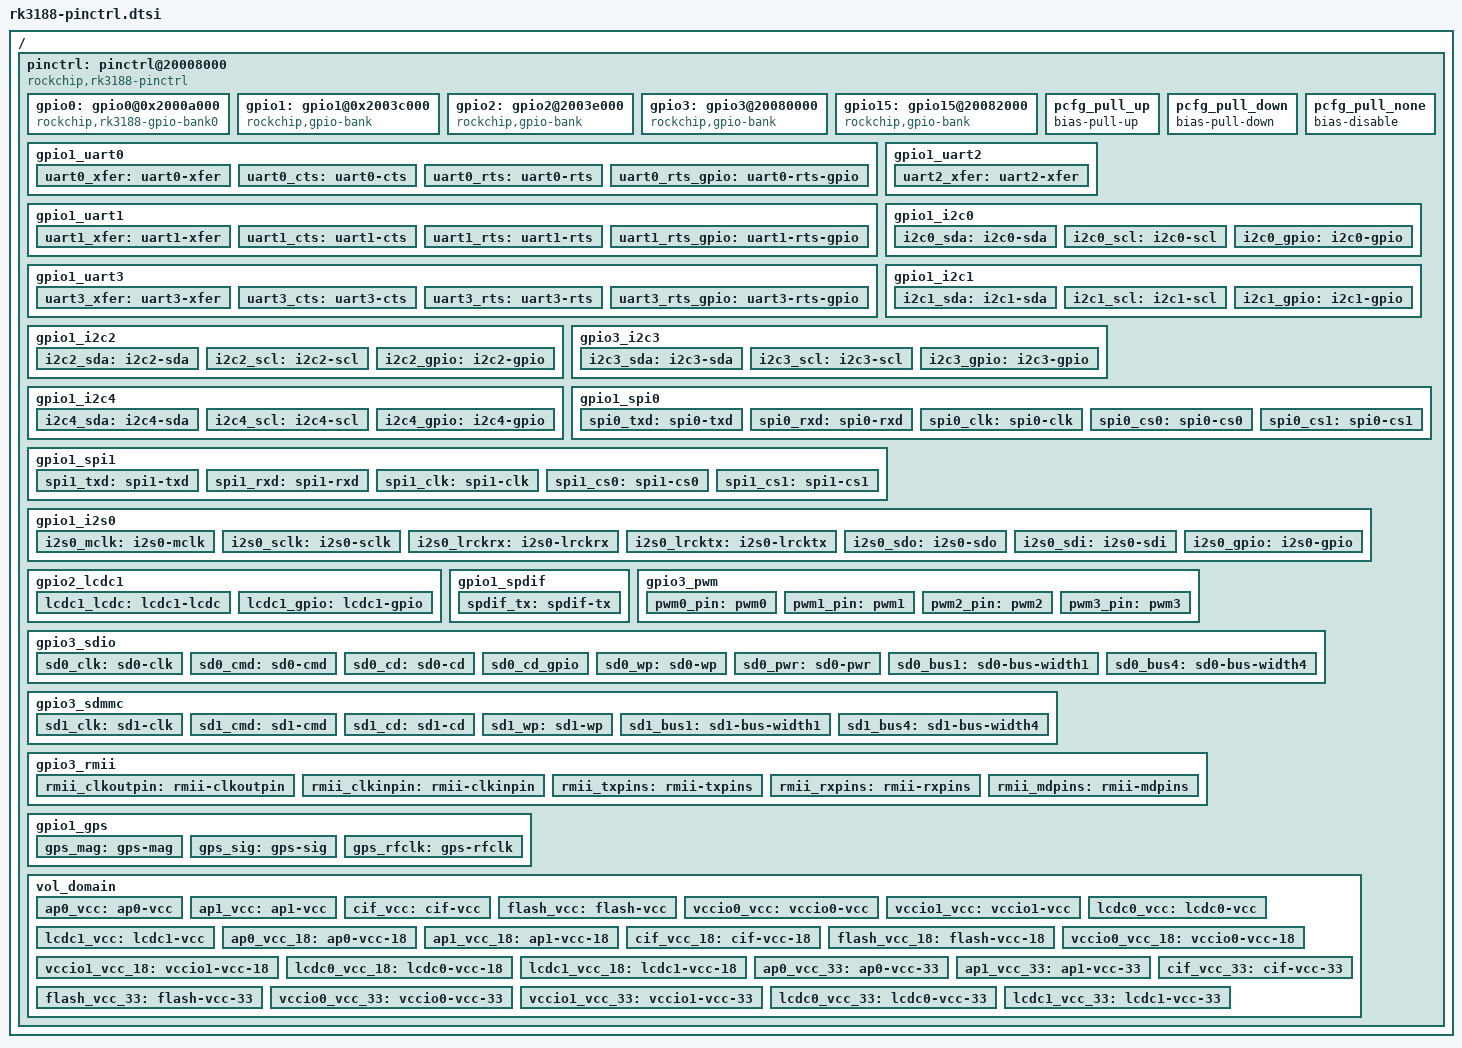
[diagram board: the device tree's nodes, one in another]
#include <dt-bindings/interrupt-controller/arm-gic.h>
#include <dt-bindings/gpio/gpio.h>
#include <dt-bindings/pinctrl/rockchip.h>
#include <dt-bindings/pinctrl/rockchip-rk3188.h>

/ { 
	pinctrl: pinctrl@20008000 {
		compatible = "rockchip,rk3188-pinctrl";
		reg = <0x20008000 0x60>,
		      <0x20008060 0x40>,
		      <0x20008164 0x40>,
		      <0x200080f4 0x10>;
		reg-names = "base", "mux", "pull", "drv";
		#address-cells = <1>;
		#size-cells = <1>;
		ranges;

		gpio0: gpio0@0x2000a000 {
			compatible = "rockchip,rk3188-gpio-bank0";
			reg = <0x2000a000 0x100>,
			      <0x20004064 0x8>;
			reg-names = "base", "pull_bank0";
			interrupts = <GIC_SPI 54 IRQ_TYPE_LEVEL_HIGH>;
			clocks = <&clk_gates8 9>;

			gpio-controller;
			#gpio-cells = <2>;

			interrupt-controller;
			#interrupt-cells = <2>;
		};

		gpio1: gpio1@0x2003c000 {
			compatible = "rockchip,gpio-bank";
			reg = <0x2003c000 0x100>;
			interrupts = <GIC_SPI 55 IRQ_TYPE_LEVEL_HIGH>;
			clocks = <&clk_gates8 10>;

			gpio-controller;
			#gpio-cells = <2>;

			interrupt-controller;
			#interrupt-cells = <2>;
		};

		gpio2: gpio2@2003e000 {
			compatible = "rockchip,gpio-bank";
			reg = <0x2003e000 0x100>;
			interrupts = <GIC_SPI 56 IRQ_TYPE_LEVEL_HIGH>;
			clocks = <&clk_gates8 11>;

			gpio-controller;
			#gpio-cells = <2>;

			interrupt-controller;
			#interrupt-cells = <2>;
		};

		gpio3: gpio3@20080000 {
			compatible = "rockchip,gpio-bank";
			reg = <0x20080000 0x100>;
			interrupts = <GIC_SPI 57 IRQ_TYPE_LEVEL_HIGH>;
			clocks = <&clk_gates8 12>;

			gpio-controller;
			#gpio-cells = <2>;

			interrupt-controller;
			#interrupt-cells = <2>;
		};

		gpio15: gpio15@20082000 {
			compatible = "rockchip,gpio-bank";
			reg = <0x20082000 0x100>;
			interrupts = <GIC_SPI 127 IRQ_TYPE_LEVEL_HIGH>;//127 = 160-32-1
			clocks = <&clk_gates8 12>;

			gpio-controller;
			#gpio-cells = <2>;

			interrupt-controller;
			#interrupt-cells = <2>;
		};

		pcfg_pull_up: pcfg_pull_up {
			bias-pull-up;
		};

		pcfg_pull_down: pcfg_pull_down {
			bias-pull-down;
		};

		pcfg_pull_none: pcfg_pull_none {
			bias-disable;
		};

		gpio1_uart0 {
			uart0_xfer: uart0-xfer {
				rockchip,pins = <UART0_SIN>,
						<UART0_SOUT>;
				rockchip,pull = <VALUE_PULL_DISABLE>;
				rockchip,voltage = <VALUE_VOL_DEFAULT>;
				rockchip,drive = <VALUE_DRV_DEFAULT>;
				//rockchip,tristate = <VALUE_TRI_DEFAULT>;
			};

			uart0_cts: uart0-cts {
				rockchip,pins = <UART0_CTSN>;
				rockchip,pull = <VALUE_PULL_DISABLE>;
				//rockchip,voltage = <VALUE_VOL_DEFAULT>;
				rockchip,drive = <VALUE_DRV_DEFAULT>;
				//rockchip,tristate = <VALUE_TRI_DEFAULT>;
			};

			uart0_rts: uart0-rts {
				rockchip,pins = <UART0_RTSN>;
				rockchip,pull = <VALUE_PULL_DISABLE>;
				//rockchip,voltage = <VALUE_VOL_DEFAULT>;
				rockchip,drive = <VALUE_DRV_DEFAULT>;
				//rockchip,tristate = <VALUE_TRI_DEFAULT>;
			};

			uart0_rts_gpio: uart0-rts-gpio {
				rockchip,pins = <FUNC_TO_GPIO(UART0_RTSN)>;
				rockchip,drive = <VALUE_DRV_DEFAULT>;
			};
		};

		gpio1_uart1 {
			uart1_xfer: uart1-xfer {
				rockchip,pins = <UART1_SIN>,
						<UART1_SOUT>;
				rockchip,pull = <VALUE_PULL_DISABLE>;
				//rockchip,voltage = <VALUE_VOL_DEFAULT>;
				rockchip,drive = <VALUE_DRV_DEFAULT>;
				//rockchip,tristate = <VALUE_TRI_DEFAULT>;
			};

			uart1_cts: uart1-cts {
				rockchip,pins = <UART1_CTSN>;
				rockchip,pull = <VALUE_PULL_DISABLE>;
				//rockchip,voltage = <VALUE_VOL_DEFAULT>;
				rockchip,drive = <VALUE_DRV_DEFAULT>;
				//rockchip,tristate = <VALUE_TRI_DEFAULT>;
			};

			uart1_rts: uart1-rts {
				rockchip,pins = <UART1_RTSN>;
				rockchip,pull = <VALUE_PULL_DISABLE>;
				//rockchip,voltage = <VALUE_VOL_DEFAULT>;
				rockchip,drive = <VALUE_DRV_DEFAULT>;
				//rockchip,tristate = <VALUE_TRI_DEFAULT>;
			};

			uart1_rts_gpio: uart1-rts-gpio {
				rockchip,pins = <FUNC_TO_GPIO(UART1_RTSN)>;
				rockchip,drive = <VALUE_DRV_DEFAULT>;
			};
		};

		gpio1_uart2 {
			uart2_xfer: uart2-xfer {
				rockchip,pins = <UART2_SIN>,
						<UART2_SOUT>;
				rockchip,pull = <VALUE_PULL_DISABLE>;
				//rockchip,voltage = <VALUE_VOL_DEFAULT>;
				rockchip,drive = <VALUE_DRV_DEFAULT>;
				//rockchip,tristate = <VALUE_TRI_DEFAULT>;
			};
			/* no rts / cts for uart2 */
		};

		gpio1_uart3 {
			uart3_xfer: uart3-xfer {
				rockchip,pins = <UART3_SIN>,
						<UART3_SOUT>;
				rockchip,pull = <VALUE_PULL_DISABLE>;
				//rockchip,voltage = <VALUE_VOL_DEFAULT>;
				rockchip,drive = <VALUE_DRV_DEFAULT>;
				//rockchip,tristate = <VALUE_TRI_DEFAULT>;
			};

			uart3_cts: uart3-cts {
				rockchip,pins = <UART3_CTSN>;
				rockchip,pull = <VALUE_PULL_DISABLE>;
				//rockchip,voltage = <VALUE_VOL_DEFAULT>;
				rockchip,drive = <VALUE_DRV_DEFAULT>;
				//rockchip,tristate = <VALUE_TRI_DEFAULT>;
			};

			uart3_rts: uart3-rts {
				rockchip,pins = <UART3_RTSN>;
				rockchip,pull = <VALUE_PULL_DISABLE>;
				//rockchip,voltage = <VALUE_VOL_DEFAULT>;
				rockchip,drive = <VALUE_DRV_DEFAULT>;
				//rockchip,tristate = <VALUE_TRI_DEFAULT>;
			};

			uart3_rts_gpio: uart3-rts-gpio {
				rockchip,pins = <FUNC_TO_GPIO(UART3_RTSN)>;
				rockchip,drive = <VALUE_DRV_DEFAULT>;
			};
		};

		gpio1_i2c0 {
			i2c0_sda:i2c0-sda {
				rockchip,pins = <I2C0_SDA>;
				rockchip,pull = <VALUE_PULL_DISABLE>;
				//rockchip,voltage = <VALUE_VOL_DEFAULT>;
				rockchip,drive = <VALUE_DRV_DEFAULT>;
				//rockchip,tristate = <VALUE_TRI_DEFAULT>;
			};

			i2c0_scl:i2c0-scl {
				rockchip,pins = <I2C0_SCL>;
				rockchip,pull = <VALUE_PULL_DISABLE>;
				//rockchip,voltage = <VALUE_VOL_DEFAULT>;
				rockchip,drive = <VALUE_DRV_DEFAULT>;
				//rockchip,tristate = <VALUE_TRI_DEFAULT>;
			};

			i2c0_gpio: i2c0-gpio {
				rockchip,pins = <FUNC_TO_GPIO(I2C0_SDA)>, <FUNC_TO_GPIO(I2C0_SCL)>;
				rockchip,drive = <VALUE_DRV_DEFAULT>;
			};
		};

		gpio1_i2c1 {
			i2c1_sda:i2c1-sda {
				rockchip,pins = <I2C1_SDA>;
				rockchip,pull = <VALUE_PULL_DISABLE>;
				rockchip,voltage = <VALUE_VOL_DEFAULT>;
				rockchip,drive = <VALUE_DRV_DEFAULT>;
				//rockchip,tristate = <VALUE_TRI_DEFAULT>;
			};

			i2c1_scl:i2c1-scl {
				rockchip,pins = <I2C1_SCL>;
				rockchip,pull = <VALUE_PULL_DISABLE>;
				rockchip,voltage = <VALUE_VOL_DEFAULT>;
				rockchip,drive = <VALUE_DRV_DEFAULT>;
				//rockchip,tristate = <VALUE_TRI_DEFAULT>;
			};

			i2c1_gpio: i2c1-gpio {
				rockchip,pins = <FUNC_TO_GPIO(I2C1_SDA)>, <FUNC_TO_GPIO(I2C1_SCL)>;
				rockchip,drive = <VALUE_DRV_DEFAULT>;
			};
		};

		gpio1_i2c2 {
			i2c2_sda:i2c2-sda {
				rockchip,pins = <I2C2_SDA>;
				rockchip,pull = <VALUE_PULL_DISABLE>;
				//rockchip,voltage = <VALUE_VOL_DEFAULT>;
				rockchip,drive = <VALUE_DRV_DEFAULT>;
				//rockchip,tristate = <VALUE_TRI_DEFAULT>;
			};

			i2c2_scl:i2c2-scl {
				rockchip,pins = <I2C2_SCL>;
				rockchip,pull = <VALUE_PULL_DISABLE>;
				//rockchip,voltage = <VALUE_VOL_DEFAULT>;
				rockchip,drive = <VALUE_DRV_DEFAULT>;
				//rockchip,tristate = <VALUE_TRI_DEFAULT>;
			};

			i2c2_gpio: i2c2-gpio {
				rockchip,pins = <FUNC_TO_GPIO(I2C2_SDA)>, <FUNC_TO_GPIO(I2C2_SCL)>;
				rockchip,drive = <VALUE_DRV_DEFAULT>;
			};
		};

		gpio3_i2c3 {
			i2c3_sda:i2c3-sda {
				rockchip,pins = <I2C3_SDA>;
				rockchip,pull = <VALUE_PULL_DISABLE>;
				//rockchip,voltage = <VALUE_VOL_DEFAULT>;
				rockchip,drive = <VALUE_DRV_DEFAULT>;
				//rockchip,tristate = <VALUE_TRI_DEFAULT>;
			};

			i2c3_scl:i2c3-scl {
				rockchip,pins = <I2C3_SCL>;
				rockchip,pull = <VALUE_PULL_DISABLE>;
				//rockchip,voltage = <VALUE_VOL_DEFAULT>;
				rockchip,drive = <VALUE_DRV_DEFAULT>;
				//rockchip,tristate = <VALUE_TRI_DEFAULT>;
			};

			i2c3_gpio: i2c3-gpio {
				rockchip,pins = <FUNC_TO_GPIO(I2C3_SDA)>, <FUNC_TO_GPIO(I2C3_SCL)>;
				rockchip,drive = <VALUE_DRV_DEFAULT>;
			};
		};

		gpio1_i2c4 {
			i2c4_sda:i2c4-sda {
				rockchip,pins = <I2C4_SDA>;
				rockchip,pull = <VALUE_PULL_DISABLE>;
				//rockchip,voltage = <VALUE_VOL_DEFAULT>;
				rockchip,drive = <VALUE_DRV_DEFAULT>;
				//rockchip,tristate = <VALUE_TRI_DEFAULT>;
			};

			i2c4_scl:i2c4-scl {
				rockchip,pins = <I2C4_SCL>;
				rockchip,pull = <VALUE_PULL_DISABLE>;
				//rockchip,voltage = <VALUE_VOL_DEFAULT>;
				rockchip,drive = <VALUE_DRV_DEFAULT>;
				//rockchip,tristate = <VALUE_TRI_DEFAULT>;
			};

			i2c4_gpio: i2c4-gpio {
				rockchip,pins = <FUNC_TO_GPIO(I2C4_SDA)>, <FUNC_TO_GPIO(I2C4_SCL)>;
				rockchip,drive = <VALUE_DRV_DEFAULT>;
			};
		};

		gpio1_spi0 {
			spi0_txd:spi0-txd {
				rockchip,pins = <SPI0_TXD>;
				rockchip,pull = <VALUE_PULL_DISABLE>;
				//rockchip,voltage = <VALUE_VOL_DEFAULT>;
				rockchip,drive = <VALUE_DRV_DEFAULT>;
				//rockchip,tristate = <VALUE_TRI_DEFAULT>;
			};

			spi0_rxd:spi0-rxd {
				rockchip,pins = <SPI0_RXD>;
				rockchip,pull = <VALUE_PULL_DISABLE>;
				//rockchip,voltage = <VALUE_VOL_DEFAULT>;
				rockchip,drive = <VALUE_DRV_DEFAULT>;
				//rockchip,tristate = <VALUE_TRI_DEFAULT>;
			};

			spi0_clk:spi0-clk {
				rockchip,pins = <SPI0_CLK>;
				rockchip,pull = <VALUE_PULL_DISABLE>;
				//rockchip,voltage = <VALUE_VOL_DEFAULT>;
				rockchip,drive = <VALUE_DRV_DEFAULT>;
				//rockchip,tristate = <VALUE_TRI_DEFAULT>;
			};

			spi0_cs0:spi0-cs0 {
				rockchip,pins = <SPI0_CS0>;
				rockchip,pull = <VALUE_PULL_DISABLE>;
				//rockchip,voltage = <VALUE_VOL_DEFAULT>;
				rockchip,drive = <VALUE_DRV_DEFAULT>;
				//rockchip,tristate = <VALUE_TRI_DEFAULT>;
			};

			spi0_cs1:spi0-cs1 {
				rockchip,pins = <SPI0_CS1>;
				rockchip,pull = <VALUE_PULL_DISABLE>;
				//rockchip,voltage = <VALUE_VOL_DEFAULT>;
				rockchip,drive = <VALUE_DRV_DEFAULT>;
				//rockchip,tristate = <VALUE_TRI_DEFAULT>;
			};

		};

		gpio1_spi1 {
			spi1_txd:spi1-txd {
				rockchip,pins = <SPI1_TXD>;
				rockchip,pull = <VALUE_PULL_DISABLE>;
				//rockchip,voltage = <VALUE_VOL_DEFAULT>;
				rockchip,drive = <VALUE_DRV_DEFAULT>;
				//rockchip,tristate = <VALUE_TRI_DEFAULT>;
			};

			spi1_rxd:spi1-rxd {
				rockchip,pins = <SPI1_RXD>;
				rockchip,pull = <VALUE_PULL_DISABLE>;
				//rockchip,voltage = <VALUE_VOL_DEFAULT>;
				rockchip,drive = <VALUE_DRV_DEFAULT>;
				//rockchip,tristate = <VALUE_TRI_DEFAULT>;
			};

			spi1_clk:spi1-clk {
				rockchip,pins = <SPI1_CLK>;
				rockchip,pull = <VALUE_PULL_DISABLE>;
				//rockchip,voltage = <VALUE_VOL_DEFAULT>;
				rockchip,drive = <VALUE_DRV_DEFAULT>;
				//rockchip,tristate = <VALUE_TRI_DEFAULT>;
			};

			spi1_cs0:spi1-cs0 {
				rockchip,pins = <SPI1_CS0>;
				rockchip,pull = <VALUE_PULL_DISABLE>;
				//rockchip,voltage = <VALUE_VOL_DEFAULT>;
				rockchip,drive = <VALUE_DRV_DEFAULT>;
				//rockchip,tristate = <VALUE_TRI_DEFAULT>;
			};

			spi1_cs1:spi1-cs1 {
				rockchip,pins = <SPI1_CS1>;
				rockchip,pull = <VALUE_PULL_DISABLE>;
				//rockchip,voltage = <VALUE_VOL_DEFAULT>;
				rockchip,drive = <VALUE_DRV_DEFAULT>;
				//rockchip,tristate = <VALUE_TRI_DEFAULT>;
			};

		};

		gpio1_i2s0 {

			i2s0_mclk:i2s0-mclk {
				rockchip,pins = <I2S0_MCLK>;
				rockchip,pull = <VALUE_PULL_DISABLE>;
				//rockchip,voltage = <VALUE_VOL_DEFAULT>;
				rockchip,drive = <VALUE_DRV_8MA>;
				//rockchip,tristate = <VALUE_TRI_DEFAULT>;

			};

			i2s0_sclk:i2s0-sclk {
				rockchip,pins = <I2S0_SCLK>;
				rockchip,pull = <VALUE_PULL_DISABLE>;
				//rockchip,voltage = <VALUE_VOL_DEFAULT>;
				rockchip,drive = <VALUE_DRV_8MA>;
				//rockchip,tristate = <VALUE_TRI_DEFAULT>;

			};

			i2s0_lrckrx:i2s0-lrckrx {
				rockchip,pins = <I2S0_LRCKRX>;
				rockchip,pull = <VALUE_PULL_DISABLE>;
				//rockchip,voltage = <VALUE_VOL_DEFAULT>;
				rockchip,drive = <VALUE_DRV_8MA>;
				//rockchip,tristate = <VALUE_TRI_DEFAULT>;

			};

			i2s0_lrcktx:i2s0-lrcktx {
				rockchip,pins = <I2S0_LRCKTX>;
				rockchip,pull = <VALUE_PULL_DISABLE>;
				//rockchip,voltage = <VALUE_VOL_DEFAULT>;
				rockchip,drive = <VALUE_DRV_8MA>;
				//rockchip,tristate = <VALUE_TRI_DEFAULT>;

			};

			i2s0_sdo:i2s0-sdo {
				rockchip,pins = <I2S0_SDO>;
				rockchip,pull = <VALUE_PULL_DISABLE>;
				//rockchip,voltage = <VALUE_VOL_DEFAULT>;
				rockchip,drive = <VALUE_DRV_8MA>;
				//rockchip,tristate = <VALUE_TRI_DEFAULT>;

			};

			i2s0_sdi:i2s0-sdi {
				rockchip,pins = <I2S0_SDI>;
				rockchip,pull = <VALUE_PULL_DISABLE>;
				//rockchip,voltage = <VALUE_VOL_DEFAULT>;
				rockchip,drive = <VALUE_DRV_8MA>;
				//rockchip,tristate = <VALUE_TRI_DEFAULT>;

			};

			i2s0_gpio: i2s0-gpio {
				rockchip,pins = <FUNC_TO_GPIO(I2S0_MCLK)>,
						<FUNC_TO_GPIO(I2S0_SCLK)>,
						<FUNC_TO_GPIO(I2S0_LRCKRX)>,
						<FUNC_TO_GPIO(I2S0_LRCKTX)>,
						<FUNC_TO_GPIO(I2S0_SDO)>,
						<FUNC_TO_GPIO(I2S0_SDI)>;
				rockchip,drive = <VALUE_DRV_8MA>;
			};
		};
	
		gpio2_lcdc1 {
			lcdc1_lcdc:lcdc1-lcdc {
				rockchip,pins = <LCDC1_D0>,
						<LCDC1_D1>,
						<LCDC1_D2>,
						<LCDC1_D3>,
						<LCDC1_D4>,
						<LCDC1_D5>,
						<LCDC1_D6>,
						<LCDC1_D7>,
						<LCDC1_D8>,
						<LCDC1_D9>,
						<LCDC1_D10>,
						<LCDC1_D11>,
						<LCDC1_D12>,
						<LCDC1_D13>,
						<LCDC1_D14>,
						<LCDC1_D15>,
						<LCDC1_D16>,
						<LCDC1_D17>,
						<LCDC1_D18>,
						<LCDC1_D19>,
						<LCDC1_D20>,
						<LCDC1_D21>,
						<LCDC1_D22>,
						<LCDC1_D23>,
						<LCDC1_DCLK>,
						<LCDC1_DEN>,
						<LCDC1_HSYNC>,
						<LCDC1_VSYNC>;
				rockchip,pull = <VALUE_PULL_DISABLE>;
				rockchip,drive = <VALUE_DRV_DEFAULT>;
			};
			
			lcdc1_gpio:lcdc1-gpio {
				rockchip,pins = <FUNC_TO_GPIO(LCDC1_D0)>,
                                                <FUNC_TO_GPIO(LCDC1_D1)>,
                                                <FUNC_TO_GPIO(LCDC1_D2)>,
                                                <FUNC_TO_GPIO(LCDC1_D3)>,
                                                <FUNC_TO_GPIO(LCDC1_D4)>,
                                                <FUNC_TO_GPIO(LCDC1_D5)>,
                                                <FUNC_TO_GPIO(LCDC1_D6)>,
                                                <FUNC_TO_GPIO(LCDC1_D7)>,
                                                <FUNC_TO_GPIO(LCDC1_D8)>,
                                                <FUNC_TO_GPIO(LCDC1_D9)>,
                                                <FUNC_TO_GPIO(LCDC1_D10)>,
                                                <FUNC_TO_GPIO(LCDC1_D11)>,
                                                <FUNC_TO_GPIO(LCDC1_D12)>,
                                                <FUNC_TO_GPIO(LCDC1_D13)>,
                                                <FUNC_TO_GPIO(LCDC1_D14)>,
                                                <FUNC_TO_GPIO(LCDC1_D15)>,
                                                <FUNC_TO_GPIO(LCDC1_D16)>,
                                                <FUNC_TO_GPIO(LCDC1_D17)>,
                                                <FUNC_TO_GPIO(LCDC1_D18)>,
                                                <FUNC_TO_GPIO(LCDC1_D19)>,
                                                <FUNC_TO_GPIO(LCDC1_D20)>,
                                                <FUNC_TO_GPIO(LCDC1_D21)>,
                                                <FUNC_TO_GPIO(LCDC1_D22)>,
                                                <FUNC_TO_GPIO(LCDC1_D23)>,
                                                <FUNC_TO_GPIO(LCDC1_DCLK)>,
                                                <FUNC_TO_GPIO(LCDC1_DEN)>,
                                                <FUNC_TO_GPIO(LCDC1_HSYNC)>,
                                                <FUNC_TO_GPIO(LCDC1_VSYNC)>;
                                rockchip,pull = <VALUE_PULL_DISABLE>;
                                rockchip,drive = <VALUE_DRV_DEFAULT>;
				
			};
			
		};

		gpio1_spdif {
			spdif_tx: spdif-tx {
				rockchip,pins = <SPDIF_TX>;
				rockchip,pull = <VALUE_PULL_DISABLE>;
				//rockchip,voltage = <VALUE_VOL_DEFAULT>;
				rockchip,drive = <VALUE_DRV_DEFAULT>;
				//rockchip,tristate = <VALUE_TRI_DEFAULT>;

			};
		};

		gpio3_pwm {
			pwm0_pin:pwm0 {
				rockchip,pins = <PWM0>;
				rockchip,pull = <VALUE_PULL_DISABLE>;
				//rockchip,voltage = <VALUE_VOL_DEFAULT>;
				rockchip,drive = <VALUE_DRV_DEFAULT>;
				//rockchip,tristate = <VALUE_TRI_DEFAULT>;

			};


			pwm1_pin:pwm1 {
				rockchip,pins = <PWM1>;
				rockchip,pull = <VALUE_PULL_DISABLE>;
				//rockchip,voltage = <VALUE_VOL_DEFAULT>;
				rockchip,drive = <VALUE_DRV_DEFAULT>;
				//rockchip,tristate = <VALUE_TRI_DEFAULT>;
			};


			pwm2_pin:pwm2 {
				rockchip,pins = <PWM2>;
				rockchip,pull = <VALUE_PULL_DISABLE>;
				//rockchip,voltage = <VALUE_VOL_DEFAULT>;
				rockchip,drive = <VALUE_DRV_DEFAULT>;
				//rockchip,tristate = <VALUE_TRI_DEFAULT>;
			};


			pwm3_pin:pwm3 {
				rockchip,pins = <PWM3>;
				rockchip,pull = <VALUE_PULL_DISABLE>;
				//rockchip,voltage = <VALUE_VOL_DEFAULT>;
				rockchip,drive = <VALUE_DRV_DEFAULT>;
				//rockchip,tristate = <VALUE_TRI_DEFAULT>;
			};

		};

		
		gpio3_sdio {
			sd0_clk: sd0-clk {
				rockchip,pins = <MMC0_CLKOUT>;
				rockchip,pull = <VALUE_PULL_DISABLE>;
				//rockchip,voltage = <VALUE_VOL_DEFAULT>;
				rockchip,drive = <VALUE_DRV_DEFAULT>;
				//rockchip,tristate = <VALUE_TRI_DEFAULT>;
			};

			sd0_cmd: sd0-cmd {
				rockchip,pins = <MMC0_CMD>;
				rockchip,pull = <VALUE_PULL_UP>;
				//rockchip,voltage = <VALUE_VOL_DEFAULT>;
				rockchip,drive = <VALUE_DRV_DEFAULT>;
				//rockchip,tristate = <VALUE_TRI_DEFAULT>;
			};

			sd0_cd: sd0-cd {
				rockchip,pins = <MMC0_DETN>;
				rockchip,pull = <VALUE_PULL_UP>;
				//rockchip,voltage = <VALUE_VOL_DEFAULT>;
				rockchip,drive = <VALUE_DRV_DEFAULT>;
				//rockchip,tristate = <VALUE_TRI_DEFAULT>;
			};

			sd0_cd_gpio:sd0_cd_gpio{
				rockchip,pins = <FUNC_TO_GPIO(MMC0_DETN)>;
				rockchip,pull = <VALUE_PULL_DISABLE>;
				rockchip,drive = <VALUE_DRV_DEFAULT>;
			};

			sd0_wp: sd0-wp {
				rockchip,pins = <MMC0_WRPRT>;
				rockchip,pull = <VALUE_PULL_DISABLE>;
				//rockchip,voltage = <VALUE_VOL_DEFAULT>;
				rockchip,drive = <VALUE_DRV_DEFAULT>;
				//rockchip,tristate = <VALUE_TRI_DEFAULT>;
			};

			sd0_pwr: sd0-pwr {
				rockchip,pins = <MMC0_PWREN>;
				rockchip,pull = <VALUE_PULL_DISABLE>;
				//rockchip,voltage = <VALUE_VOL_DEFAULT>;
				rockchip,drive = <VALUE_DRV_DEFAULT>;
				//rockchip,tristate = <VALUE_TRI_DEFAULT>;
			};

			sd0_bus1: sd0-bus-width1 {
				rockchip,pins = <MMC0_D0>;
				rockchip,pull = <VALUE_PULL_UP>;
				//rockchip,voltage = <VALUE_VOL_DEFAULT>;
				rockchip,drive = <VALUE_DRV_DEFAULT>;
				//rockchip,tristate = <VALUE_TRI_DEFAULT>;
			};

			sd0_bus4: sd0-bus-width4 {
				rockchip,pins = <MMC0_D0>,
						<MMC0_D1>,
						<MMC0_D2 >,
						<MMC0_D3>;
				rockchip,pull = <VALUE_PULL_UP>;
				//rockchip,voltage = <VALUE_VOL_DEFAULT>;
				rockchip,drive = <VALUE_DRV_DEFAULT>;
				//rockchip,tristate = <VALUE_TRI_DEFAULT>;
			};
		};

		gpio3_sdmmc {
			sd1_clk: sd1-clk {
				rockchip,pins = <MMC1_CLKOUT>;
				rockchip,pull = <VALUE_PULL_DISABLE>;
				//rockchip,voltage = <VALUE_VOL_DEFAULT>;
				rockchip,drive = <VALUE_DRV_DEFAULT>;
				//rockchip,tristate = <VALUE_TRI_DEFAULT>;
			};

			sd1_cmd: sd1-cmd {
				rockchip,pins = <MMC1_CMD>;
				rockchip,pull = <VALUE_PULL_UP>;
				//rockchip,voltage = <VALUE_VOL_DEFAULT>;
				rockchip,drive = <VALUE_DRV_DEFAULT>;
				//rockchip,tristate = <VALUE_TRI_DEFAULT>;
			};

			sd1_cd: sd1-cd {
				rockchip,pins = <MMC1_DETN>;
				rockchip,pull = <VALUE_PULL_UP>;
				//rockchip,voltage = <VALUE_VOL_DEFAULT>;
				rockchip,drive = <VALUE_DRV_DEFAULT>;
				//rockchip,tristate = <VALUE_TRI_DEFAULT>;
			};

			sd1_wp: sd1-wp {
				rockchip,pins = <MMC1_WRPRT>;
				rockchip,pull = <VALUE_PULL_DISABLE>;
				//rockchip,voltage = <VALUE_VOL_DEFAULT>;
				rockchip,drive = <VALUE_DRV_DEFAULT>;
				//rockchip,tristate = <VALUE_TRI_DEFAULT>;
			};

			sd1_bus1: sd1-bus-width1 {
				rockchip,pins = <MMC1_D0>;
				rockchip,pull = <VALUE_PULL_UP>;
				//rockchip,voltage = <VALUE_VOL_DEFAULT>;
				rockchip,drive = <VALUE_DRV_DEFAULT>;
				//rockchip,tristate = <VALUE_TRI_DEFAULT>;
			};

			sd1_bus4: sd1-bus-width4 {
				rockchip,pins = <MMC1_D0>,
						<MMC1_D1>,
						<MMC1_D2>,
						<MMC1_D3>;
				rockchip,pull = <VALUE_PULL_UP>;
				//rockchip,voltage = <VALUE_VOL_DEFAULT>;
				rockchip,drive = <VALUE_DRV_DEFAULT>;
				//rockchip,tristate = <VALUE_TRI_DEFAULT>;
			};
		};

		gpio3_rmii {
			rmii_clkoutpin: rmii-clkoutpin {
				rockchip,pins = <RMII_CLKOUT>;
				rockchip,pull = <VALUE_PULL_DISABLE>;
				//rockchip,voltage = <VALUE_VOL_DEFAULT>;
				rockchip,drive = <VALUE_DRV_DEFAULT>;
				//rockchip,tristate = <VALUE_TRI_DEFAULT>;
			};

			rmii_clkinpin: rmii-clkinpin {
				rockchip,pins = <RMII_CLKIN>;
				rockchip,pull = <VALUE_PULL_DISABLE>;
				//rockchip,voltage = <VALUE_VOL_DEFAULT>;
				rockchip,drive = <VALUE_DRV_DEFAULT>;
				//rockchip,tristate = <VALUE_TRI_DEFAULT>;
			};

			rmii_txpins: rmii-txpins {
				rockchip,pins = <RMII_TXEN>, <RMII_TXD1>, <RMII_TXD0>;
				rockchip,pull = <VALUE_PULL_DISABLE>;
				//rockchip,voltage = <VALUE_VOL_DEFAULT>;
				rockchip,drive = <VALUE_DRV_DEFAULT>;
				//rockchip,tristate = <VALUE_TRI_DEFAULT>;
			};

			rmii_rxpins: rmii-rxpins {
				rockchip,pins = <RMII_RXD0>, <RMII_RXD1>, <RMII_RXERR>, <RMII_CRS>;
				rockchip,pull = <VALUE_PULL_DISABLE>;
				//rockchip,voltage = <VALUE_VOL_DEFAULT>;
				rockchip,drive = <VALUE_DRV_DEFAULT>;
				//rockchip,tristate = <VALUE_TRI_DEFAULT>;
			};

			rmii_mdpins: rmii-mdpins {
				rockchip,pins = <RMII_MD>, <RMII_MDCLK>;
				rockchip,pull = <VALUE_PULL_DISABLE>;
				//rockchip,voltage = <VALUE_VOL_DEFAULT>;
				rockchip,drive = <VALUE_DRV_DEFAULT>;
				//rockchip,tristate = <VALUE_TRI_DEFAULT>;
			};
		};

		gpio1_gps {
			gps_mag:gps-mag {
				rockchip,pins = <GPS_MAG>;
				rockchip,pull = <VALUE_PULL_DISABLE>;
				//rockchip,voltage = <VALUE_VOL_DEFAULT>;
				rockchip,drive = <VALUE_DRV_DEFAULT>;
				//rockchip,tristate = <VALUE_TRI_DEFAULT>;

			};

			gps_sig:gps-sig {
				rockchip,pins = <GPS_SIG>;
				rockchip,pull = <VALUE_PULL_DISABLE>;
				//rockchip,voltage = <VALUE_VOL_DEFAULT>;
				rockchip,drive = <VALUE_DRV_DEFAULT>;
				//rockchip,tristate = <VALUE_TRI_DEFAULT>;

			};


			gps_rfclk:gps-rfclk {
				rockchip,pins = <GPS_RFCLK>;
				rockchip,pull = <VALUE_PULL_DISABLE>;
				//rockchip,voltage = <VALUE_VOL_DEFAULT>;
				rockchip,drive = <VALUE_DRV_DEFAULT>;
				//rockchip,tristate = <VALUE_TRI_DEFAULT>;

			};

		};

		vol_domain {
			ap0_vcc:ap0-vcc {
				rockchip,pins = <VIRTUAL_PIN_FOR_AP0_VCC>;
				rockchip,voltage = <VALUE_VOL_DEFAULT>;
			};
			
			ap1_vcc:ap1-vcc {
				rockchip,pins = <VIRTUAL_PIN_FOR_AP1_VCC>;
				rockchip,voltage = <VALUE_VOL_DEFAULT>;
			};
			
			cif_vcc:cif-vcc {
				rockchip,pins = <VIRTUAL_PIN_FOR_CIF_VCC>;
				rockchip,voltage = <VALUE_VOL_DEFAULT>;
			};

			flash_vcc:flash-vcc {
				rockchip,pins = <VIRTUAL_PIN_FOR_FLASH_VCC>;
				rockchip,voltage = <VALUE_VOL_DEFAULT>;
			};
			
			vccio0_vcc:vccio0-vcc {
				rockchip,pins = <VIRTUAL_PIN_FOR_VCCIO0_VCC>;
				rockchip,voltage = <VALUE_VOL_DEFAULT>; 
			};

			vccio1_vcc:vccio1-vcc {
				rockchip,pins = <VIRTUAL_PIN_FOR_VCCIO1_VCC>;
				rockchip,voltage = <VALUE_VOL_DEFAULT>; 
			};

			lcdc0_vcc:lcdc0-vcc {
				rockchip,pins = <VIRTUAL_PIN_FOR_LCDC0_VCC>;
				rockchip,voltage = <VALUE_VOL_DEFAULT>;
			};

			lcdc1_vcc:lcdc1-vcc {
				rockchip,pins = <VIRTUAL_PIN_FOR_LCDC1_VCC>;
				rockchip,voltage = <VALUE_VOL_DEFAULT>;
			};

			
			
			ap0_vcc_18:ap0-vcc-18 {
				rockchip,pins = <VIRTUAL_PIN_FOR_AP0_VCC>;
				rockchip,voltage = <VALUE_VOL_1V8>;
			};
			
			ap1_vcc_18:ap1-vcc-18 {
				rockchip,pins = <VIRTUAL_PIN_FOR_AP1_VCC>;
				rockchip,voltage = <VALUE_VOL_1V8>;
			};
			
			cif_vcc_18:cif-vcc-18 {
				rockchip,pins = <VIRTUAL_PIN_FOR_CIF_VCC>;
				rockchip,voltage = <VALUE_VOL_1V8>;
			};

			flash_vcc_18:flash-vcc-18 {
				rockchip,pins = <VIRTUAL_PIN_FOR_FLASH_VCC>;
				rockchip,voltage = <VALUE_VOL_1V8>;
			};
			
			vccio0_vcc_18:vccio0-vcc-18 {
				rockchip,pins = <VIRTUAL_PIN_FOR_VCCIO0_VCC>;
				rockchip,voltage = <VALUE_VOL_1V8>; 
			};

			vccio1_vcc_18:vccio1-vcc-18 {
				rockchip,pins = <VIRTUAL_PIN_FOR_VCCIO1_VCC>;
				rockchip,voltage = <VALUE_VOL_1V8>; 
			};

			lcdc0_vcc_18:lcdc0-vcc-18 {
				rockchip,pins = <VIRTUAL_PIN_FOR_LCDC0_VCC>;
				rockchip,voltage = <VALUE_VOL_1V8>;
			};

			lcdc1_vcc_18:lcdc1-vcc-18 {
				rockchip,pins = <VIRTUAL_PIN_FOR_LCDC1_VCC>;
				rockchip,voltage = <VALUE_VOL_1V8>;
			};

			

			ap0_vcc_33:ap0-vcc-33 {
				rockchip,pins = <VIRTUAL_PIN_FOR_AP0_VCC>;
				rockchip,voltage = <VALUE_VOL_3V3>;
			};
			
			ap1_vcc_33:ap1-vcc-33 {
				rockchip,pins = <VIRTUAL_PIN_FOR_AP1_VCC>;
				rockchip,voltage = <VALUE_VOL_3V3>;
			};
			
			cif_vcc_33:cif-vcc-33 {
				rockchip,pins = <VIRTUAL_PIN_FOR_CIF_VCC>;
				rockchip,voltage = <VALUE_VOL_3V3>;
			};

			flash_vcc_33:flash-vcc-33 {
				rockchip,pins = <VIRTUAL_PIN_FOR_FLASH_VCC>;
				rockchip,voltage = <VALUE_VOL_3V3>;
			};
			
			vccio0_vcc_33:vccio0-vcc-33 {
				rockchip,pins = <VIRTUAL_PIN_FOR_VCCIO0_VCC>;
				rockchip,voltage = <VALUE_VOL_3V3>; 
			};

			vccio1_vcc_33:vccio1-vcc-33 {
				rockchip,pins = <VIRTUAL_PIN_FOR_VCCIO1_VCC>;
				rockchip,voltage = <VALUE_VOL_3V3>; 
			};

			lcdc0_vcc_33:lcdc0-vcc-33 {
				rockchip,pins = <VIRTUAL_PIN_FOR_LCDC0_VCC>;
				rockchip,voltage = <VALUE_VOL_3V3>;
			};

			lcdc1_vcc_33:lcdc1-vcc-33 {
				rockchip,pins = <VIRTUAL_PIN_FOR_LCDC1_VCC>;
				rockchip,voltage = <VALUE_VOL_3V3>;
			};


		};

		//to add
	};
};
